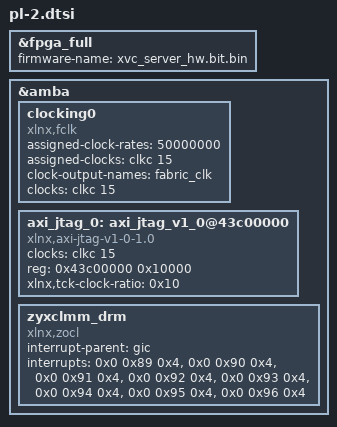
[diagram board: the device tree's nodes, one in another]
/*
 * CAUTION: This file is automatically generated by Xilinx.
 * Version: XSCT 2023.2
 * Today is: Wed Apr 10 17:11:53 2024
 */


/dts-v1/;
/plugin/;
&fpga_full {
	firmware-name = "xvc_server_hw.bit.bin";
};
&amba {
	#address-cells = <1>;
	#size-cells = <1>;
	clocking0: clocking0 {
		#clock-cells = <0>;
		assigned-clock-rates = <50000000>;
		assigned-clocks = <&clkc 15>;
		clock-output-names = "fabric_clk";
		clocks = <&clkc 15>;
		compatible = "xlnx,fclk";
	};
	axi_jtag_0: axi_jtag_v1_0@43c00000 {
		/* This is a place holder node for a custom IP, user may need to update the entries */
		clock-names = "s_axi_aclk";
		clocks = <&clkc 15>;
		compatible = "xlnx,axi-jtag-v1-0-1.0";
		reg = <0x43c00000 0x10000>;
		xlnx,tck-clock-ratio = <0x10>;
	};
	zyxclmm_drm {
		compatible = "xlnx,zocl";
		interrupt-parent = <&gic>;
		interrupts = <0x0 0x89 0x4>, <0x0 0x90 0x4>, <0x0 0x91 0x4>, <0x0 0x92 0x4>, <0x0 0x93 0x4>, <0x0 0x94 0x4>, <0x0 0x95 0x4>, <0x0 0x96 0x4>;
	};
};
